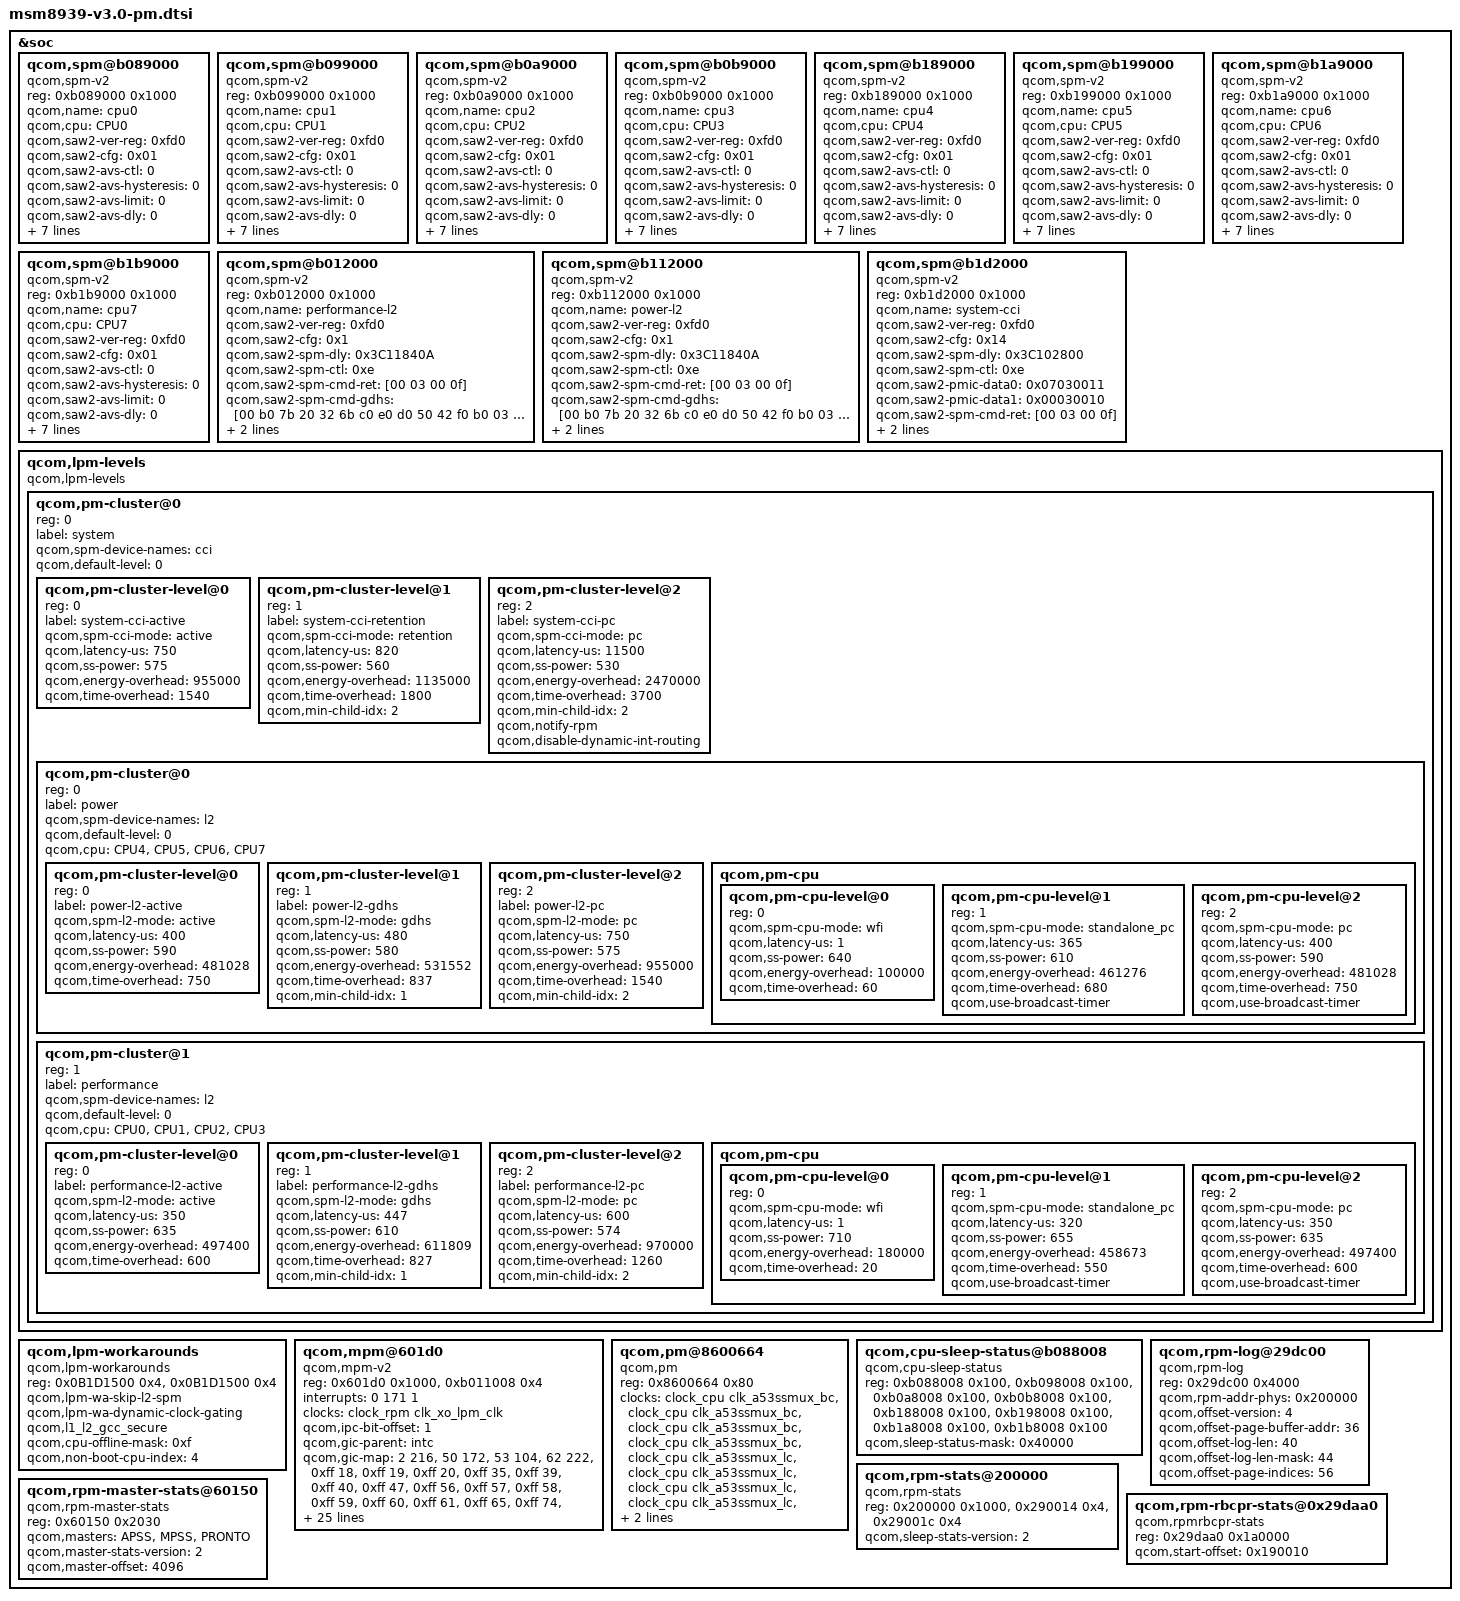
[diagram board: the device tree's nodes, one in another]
/* Copyright (c) 2014-2015, The Linux Foundation. All rights reserved.
 *
 * This program is free software; you can redistribute it and/or modify
 * it under the terms of the GNU General Public License version 2 and
 * only version 2 as published by the Free Software Foundation.
 *
 * This program is distributed in the hope that it will be useful,
 * but WITHOUT ANY WARRANTY; without even the implied warranty of
 * MERCHANTABILITY or FITNESS FOR A PARTICULAR PURPOSE.  See the
 * GNU General Public License for more details.
 */

&soc {
	qcom,spm@b089000 {
		compatible = "qcom,spm-v2";
		reg = <0xb089000 0x1000>;
		qcom,name = "cpu0";
		qcom,cpu = <&CPU0>;
		qcom,saw2-ver-reg = <0xfd0>;
		qcom,saw2-cfg = <0x01>;
		qcom,saw2-avs-ctl = <0>;
		qcom,saw2-avs-hysteresis = <0>;
		qcom,saw2-avs-limit = <0>;
		qcom,saw2-avs-dly= <0>;
		qcom,saw2-spm-dly= <0x3c102800>;
		qcom,saw2-spm-ctl = <0xe>;
		qcom,saw2-spm-cmd-wfi = [60 03 60 0b 0f];
		qcom,saw2-spm-cmd-spc = [20 50 1b 10 80 30 90 5b 60 50 03 60
				76 76 0b 50 1b 94 5B 80 10 26 30 50 0f];
		qcom,saw2-spm-cmd-pc = [20 50 1b 10 80 30 90 5b 60 50 03 60
				76 76 0b 50 1b 94 5B 80 10 26 30 50 0f];
	};

	qcom,spm@b099000 {
		compatible = "qcom,spm-v2";
		reg = <0xb099000 0x1000>;
		qcom,name = "cpu1";
		qcom,cpu = <&CPU1>;
		qcom,saw2-ver-reg = <0xfd0>;
		qcom,saw2-cfg = <0x01>;
		qcom,saw2-avs-ctl = <0>;
		qcom,saw2-avs-hysteresis = <0>;
		qcom,saw2-avs-limit = <0>;
		qcom,saw2-avs-dly= <0>;
		qcom,saw2-spm-dly= <0x3c102800>;
		qcom,saw2-spm-ctl = <0xe>;
		qcom,saw2-spm-cmd-wfi = [60 03 60 0b 0f];
		qcom,saw2-spm-cmd-spc = [20 50 1b 10 80 30 90 5b 60 50 03 60
				76 76 0b 50 1b 94 5B 80 10 26 30 50 0f];
		qcom,saw2-spm-cmd-pc = [20 50 1b 10 80 30 90 5b 60 50 03 60
				76 76 0b 50 1b 94 5B 80 10 26 30 50 0f];
	};

	qcom,spm@b0a9000 {
		compatible = "qcom,spm-v2";
		reg = <0xb0a9000 0x1000>;
		qcom,name = "cpu2";
		qcom,cpu = <&CPU2>;
		qcom,saw2-ver-reg = <0xfd0>;
		qcom,saw2-cfg = <0x01>;
		qcom,saw2-avs-ctl = <0>;
		qcom,saw2-avs-hysteresis = <0>;
		qcom,saw2-avs-limit = <0>;
		qcom,saw2-avs-dly= <0>;
		qcom,saw2-spm-dly= <0x3c102800>;
		qcom,saw2-spm-ctl = <0xe>;
		qcom,saw2-spm-cmd-wfi = [60 03 60 0b 0f];
		qcom,saw2-spm-cmd-spc = [20 50 1b 10 80 30 90 5b 60 50 03 60
				76 76 0b 50 1b 94 5B 80 10 26 30 50 0f];
		qcom,saw2-spm-cmd-pc = [20 50 1b 10 80 30 90 5b 60 50 03 60
				76 76 0b 50 1b 94 5B 80 10 26 30 50 0f];
	};

	qcom,spm@b0b9000 {
		compatible = "qcom,spm-v2";
		reg = <0xb0b9000 0x1000>;
		qcom,name = "cpu3";
		qcom,cpu = <&CPU3>;
		qcom,saw2-ver-reg = <0xfd0>;
		qcom,saw2-cfg = <0x01>;
		qcom,saw2-avs-ctl = <0>;
		qcom,saw2-avs-hysteresis = <0>;
		qcom,saw2-avs-limit = <0>;
		qcom,saw2-avs-dly= <0>;
		qcom,saw2-spm-dly= <0x3c102800>;
		qcom,saw2-spm-ctl = <0xe>;
		qcom,saw2-spm-cmd-wfi = [60 03 60 0b 0f];
		qcom,saw2-spm-cmd-spc = [20 50 1b 10 80 30 90 5b 60 50 03 60
				76 76 0b 50 1b 94 5B 80 10 26 30 50 0f];
		qcom,saw2-spm-cmd-pc = [20 50 1b 10 80 30 90 5b 60 50 03 60
				76 76 0b 50 1b 94 5B 80 10 26 30 50 0f];
	};

	qcom,spm@b189000 {
		compatible = "qcom,spm-v2";
		reg = <0xb189000 0x1000>;
		qcom,name = "cpu4";
		qcom,cpu = <&CPU4>;
		qcom,saw2-ver-reg = <0xfd0>;
		qcom,saw2-cfg = <0x01>;
		qcom,saw2-avs-ctl = <0>;
		qcom,saw2-avs-hysteresis = <0>;
		qcom,saw2-avs-limit = <0>;
		qcom,saw2-avs-dly= <0>;
		qcom,saw2-spm-dly= <0x3c102800>;
		qcom,saw2-spm-ctl = <0xe>;
		qcom,saw2-spm-cmd-wfi = [60 03 60 0b 0f];
		qcom,saw2-spm-cmd-spc = [20 50 1b 10 80 30 90 5b 60 50 03 60
				76 76 0b 50 1b 94 5B 80 10 26 30 50 0f];
		qcom,saw2-spm-cmd-pc = [20 50 1b 10 80 30 90 5b 60 50 03 60
				76 76 0b 50 1b 94 5B 80 10 26 30 50 0f];
	};

	qcom,spm@b199000 {
		compatible = "qcom,spm-v2";
		reg = <0xb199000 0x1000>;
		qcom,name = "cpu5";
		qcom,cpu = <&CPU5>;
		qcom,saw2-ver-reg = <0xfd0>;
		qcom,saw2-cfg = <0x01>;
		qcom,saw2-avs-ctl = <0>;
		qcom,saw2-avs-hysteresis = <0>;
		qcom,saw2-avs-limit = <0>;
		qcom,saw2-avs-dly= <0>;
		qcom,saw2-spm-dly= <0x3c102800>;
		qcom,saw2-spm-ctl = <0xe>;
		qcom,saw2-spm-cmd-wfi = [60 03 60 0b 0f];
		qcom,saw2-spm-cmd-spc = [20 50 1b 10 80 30 90 5b 60 50 03 60
				76 76 0b 50 1b 94 5B 80 10 26 30 50 0f];
		qcom,saw2-spm-cmd-pc = [20 50 1b 10 80 30 90 5b 60 50 03 60
				76 76 0b 50 1b 94 5B 80 10 26 30 50 0f];
	};

	qcom,spm@b1a9000 {
		compatible = "qcom,spm-v2";
		reg = <0xb1a9000 0x1000>;
		qcom,name = "cpu6";
		qcom,cpu = <&CPU6>;
		qcom,saw2-ver-reg = <0xfd0>;
		qcom,saw2-cfg = <0x01>;
		qcom,saw2-avs-ctl = <0>;
		qcom,saw2-avs-hysteresis = <0>;
		qcom,saw2-avs-limit = <0>;
		qcom,saw2-avs-dly= <0>;
		qcom,saw2-spm-dly= <0x3c102800>;
		qcom,saw2-spm-ctl = <0xe>;
		qcom,saw2-spm-cmd-wfi = [60 03 60 0b 0f];
		qcom,saw2-spm-cmd-spc = [20 50 1b 10 80 30 90 5b 60 50 03 60
				76 76 0b 50 1b 94 5B 80 10 26 30 50 0f];
		qcom,saw2-spm-cmd-pc = [20 50 1b 10 80 30 90 5b 60 50 03 60
				76 76 0b 50 1b 94 5B 80 10 26 30 50 0f];
	};

	qcom,spm@b1b9000 {
		compatible = "qcom,spm-v2";
		reg = <0xb1b9000 0x1000>;
		qcom,name = "cpu7";
		qcom,cpu = <&CPU7>;
		qcom,saw2-ver-reg = <0xfd0>;
		qcom,saw2-cfg = <0x01>;
		qcom,saw2-avs-ctl = <0>;
		qcom,saw2-avs-hysteresis = <0>;
		qcom,saw2-avs-limit = <0>;
		qcom,saw2-avs-dly= <0>;
		qcom,saw2-spm-dly= <0x3c102800>;
		qcom,saw2-spm-ctl = <0xe>;
		qcom,saw2-spm-cmd-wfi = [60 03 60 0b 0f];
		qcom,saw2-spm-cmd-spc = [20 50 1b 10 80 30 90 5b 60 50 03 60
				76 76 0b 50 1b 94 5B 80 10 26 30 50 0f];
		qcom,saw2-spm-cmd-pc = [20 50 1b 10 80 30 90 5b 60 50 03 60
				76 76 0b 50 1b 94 5B 80 10 26 30 50 0f];
	};

	qcom,spm@b012000 {
		compatible = "qcom,spm-v2";
		reg = <0xb012000 0x1000>;
		qcom,name = "performance-l2";
		qcom,saw2-ver-reg = <0xfd0>;
		qcom,saw2-cfg = <0x1>;
		qcom,saw2-spm-dly= <0x3C11840A>;
		qcom,saw2-spm-ctl = <0xe>;
		qcom,saw2-spm-cmd-ret = [00 03 00 0f];
		qcom,saw2-spm-cmd-gdhs = [00 b0 7b 20 32 6b c0 e0 d0 50 42 f0 b0
			03 1f 1b b0 7b 4e 02 02 d0 e0 c0 22 6b 02 32 52
			f0 b0 0f];
		qcom,saw2-spm-cmd-pc = [00 b0 7b 32 10 e0 d0 6b c0 50 42 b0 03
			1f 1b b0 7b 4e 02 02 c0 d0 12 e0 6b 02 32 50 b0 0f];
	};

	qcom,spm@b112000 {
		compatible = "qcom,spm-v2";
		reg = <0xb112000 0x1000>;
		qcom,name = "power-l2";
		qcom,saw2-ver-reg = <0xfd0>;
		qcom,saw2-cfg = <0x1>;
		qcom,saw2-spm-dly= <0x3C11840A>;
		qcom,saw2-spm-ctl = <0xe>;
		qcom,saw2-spm-cmd-ret = [00 03 00 0f];
		qcom,saw2-spm-cmd-gdhs = [00 b0 7b 20 32 6b c0 e0 d0 50 42 f0 b0
			03 1f 1b b0 7b 4e 02 02 d0 e0 c0 22 6b 02 32 52
			f0 b0 0f];
		qcom,saw2-spm-cmd-pc = [00 b0 7b 32 10 e0 d0 6b c0 50 42 b0 03
			1f 1b b0 7b 4e 02 02 c0 d0 12 e0 6b 02 32 50 b0 0f];
	};

	qcom,spm@b1d2000 {
		compatible = "qcom,spm-v2";
		reg = <0xb1d2000 0x1000>;
		qcom,name = "system-cci";
		qcom,saw2-ver-reg = <0xfd0>;
		qcom,saw2-cfg = <0x14>;
		qcom,saw2-spm-dly= <0x3C102800>;
		qcom,saw2-spm-ctl = <0xe>;
		qcom,saw2-pmic-data0 = <0x07030011>;
		qcom,saw2-pmic-data1 = <0x00030010>;
                qcom,saw2-spm-cmd-ret = [00 03 00 0f];
                qcom,saw2-spm-cmd-pc = [00 60 50 11 07 70 7B 01 50
                                02 62 72 0f];
	};

	qcom,lpm-levels {
		compatible = "qcom,lpm-levels";
		#address-cells = <1>;
		#size-cells = <0>;

		qcom,pm-cluster@0 {
			reg = <0>;
			#address-cells = <1>;
			#size-cells = <0>;
			label = "system";
			qcom,spm-device-names = "cci";
			qcom,default-level=<0>;

			qcom,pm-cluster-level@0{
				reg = <0>;
				label = "system-cci-active";
				qcom,spm-cci-mode = "active";
				qcom,latency-us = <750>;
				qcom,ss-power = <575>;
				qcom,energy-overhead = <955000>;
				qcom,time-overhead = <1540>;
			};

			qcom,pm-cluster-level@1{
				reg = <1>;
				label = "system-cci-retention";
				qcom,spm-cci-mode = "retention";
				qcom,latency-us = <820>;
				qcom,ss-power = <560>;
				qcom,energy-overhead = <1135000>;
				qcom,time-overhead = <1800>;
				qcom,min-child-idx = <2>;
			};

			qcom,pm-cluster-level@2{
				reg = <2>;
				label = "system-cci-pc";
				qcom,spm-cci-mode = "pc";
				qcom,latency-us = <11500>;
				qcom,ss-power = <530>;
				qcom,energy-overhead = <2470000>;
				qcom,time-overhead = <3700>;
				qcom,min-child-idx = <2>;
				qcom,notify-rpm;
				qcom,disable-dynamic-int-routing;
			};

			qcom,pm-cluster@0{
				reg = <0>;
				#address-cells = <1>;
				#size-cells = <0>;
				label = "power";
				qcom,spm-device-names = "l2";
				qcom,default-level=<0>;
				qcom,cpu = <&CPU4 &CPU5 &CPU6 &CPU7>;

				qcom,pm-cluster-level@0{
					reg = <0>;
					label = "power-l2-active";
					qcom,spm-l2-mode = "active";
					qcom,latency-us = <400>;
					qcom,ss-power = <590>;
					qcom,energy-overhead = <481028>;
					qcom,time-overhead = <750>;
				};

				qcom,pm-cluster-level@1{
					reg = <1>;
					label = "power-l2-gdhs";
					qcom,spm-l2-mode = "gdhs";
					qcom,latency-us = <480>;
					qcom,ss-power = <580>;
					qcom,energy-overhead = <531552>;
					qcom,time-overhead = <837>;
					qcom,min-child-idx = <1>;
				};

				qcom,pm-cluster-level@2{
					reg = <2>;
					label = "power-l2-pc";
					qcom,spm-l2-mode = "pc";
					qcom,latency-us = <750>;
					qcom,ss-power = <575>;
					qcom,energy-overhead = <955000>;
					qcom,time-overhead = <1540>;
					qcom,min-child-idx = <2>;
				};

				qcom,pm-cpu {
					#address-cells = <1>;
					#size-cells = <0>;

					qcom,pm-cpu-level@0 {
						reg = <0>;
						qcom,spm-cpu-mode = "wfi";
						qcom,latency-us = <1>;
						qcom,ss-power = <640>;
						qcom,energy-overhead = <100000>;
						qcom,time-overhead = <60>;
					};

					qcom,pm-cpu-level@1 {
						reg = <1>;
						qcom,spm-cpu-mode = "standalone_pc";
						qcom,latency-us = <365>;
						qcom,ss-power = <610>;
						qcom,energy-overhead = <461276>;
						qcom,time-overhead = <680>;
						qcom,use-broadcast-timer;
					};

					qcom,pm-cpu-level@2 {
						reg = <2>;
						qcom,spm-cpu-mode = "pc";
						qcom,latency-us = <400>;
						qcom,ss-power = <590>;
						qcom,energy-overhead = <481028>;
						qcom,time-overhead = <750>;
						qcom,use-broadcast-timer;
					};
				};
			};

			qcom,pm-cluster@1{
				reg = <1>;
				#address-cells = <1>;
				#size-cells = <0>;
				label = "performance";
				qcom,spm-device-names = "l2";
				qcom,default-level=<0>;
				qcom,cpu = <&CPU0 &CPU1 &CPU2 &CPU3>;

				qcom,pm-cluster-level@0{
					reg = <0>;
					label = "performance-l2-active";
					qcom,spm-l2-mode = "active";
					qcom,latency-us = <350>;
					qcom,ss-power = <635>;
					qcom,energy-overhead = <497400>;
					qcom,time-overhead = <600>;
				};

				qcom,pm-cluster-level@1{
					reg = <1>;
					label = "performance-l2-gdhs";
					qcom,spm-l2-mode = "gdhs";
					qcom,latency-us = <447>;
					qcom,ss-power = <610>;
					qcom,energy-overhead = <611809>;
					qcom,time-overhead = <827>;
					qcom,min-child-idx = <1>;
				};

				qcom,pm-cluster-level@2{
					reg = <2>;
					label = "performance-l2-pc";
					qcom,spm-l2-mode = "pc";
					qcom,latency-us = <600>;
					qcom,ss-power = <574>;
					qcom,energy-overhead = <970000>;
					qcom,time-overhead = <1260>;
					qcom,min-child-idx = <2>;
				};

				qcom,pm-cpu {
					#address-cells = <1>;
					#size-cells = <0>;

					qcom,pm-cpu-level@0 {
						reg = <0>;
						qcom,spm-cpu-mode = "wfi";
						qcom,latency-us = <1>;
						qcom,ss-power = <710>;
						qcom,energy-overhead = <180000>;
						qcom,time-overhead = <20>;
					};

					qcom,pm-cpu-level@1 {
						reg = <1>;
						qcom,spm-cpu-mode = "standalone_pc";
						qcom,latency-us = <320>;
						qcom,ss-power = <655>;
						qcom,energy-overhead = <458673>;
						qcom,time-overhead = <550>;
						qcom,use-broadcast-timer;
					};

					qcom,pm-cpu-level@2 {
						reg = <2>;
						qcom,spm-cpu-mode = "pc";
						qcom,latency-us = <350>;
						qcom,ss-power = <635>;
						qcom,energy-overhead = <497400>;
						qcom,time-overhead = <600>;
						qcom,use-broadcast-timer;
					};
				};
			};
		};
	};

	qcom,lpm-workarounds {
		compatible = "qcom,lpm-workarounds";
		reg = <0x0B1D1500 0x4>,
		      <0x0B1D1500 0x4>;
		reg-names = "l2-pwr-sts", "l1-l2-gcc";
		qcom,lpm-wa-skip-l2-spm;
		qcom,lpm-wa-dynamic-clock-gating;
		qcom,l1_l2_gcc_secure;
		qcom,cpu-offline-mask = <0xf>;
		qcom,non-boot-cpu-index = <4>;
	};

	qcom,mpm@601d0 {
		compatible = "qcom,mpm-v2";
		reg = <0x601d0 0x1000>, /* MSM_RPM_MPM_BASE 4K */
		    <0xb011008 0x4>;
		reg-names = "vmpm", "ipc";
		interrupts = <0 171 1>;
		clocks = <&clock_rpm clk_xo_lpm_clk>;
		clock-names = "xo";

		qcom,ipc-bit-offset = <1>;

		qcom,gic-parent = <&intc>;
		qcom,gic-map = <2 216>, /* tsens_upper_lower_int */
			<50 172>, /* usb1_hs_async_wakeup_irq */
			<53 104>, /* mdss_irq */
			<62 222>, /* ee0_krait_hlos_spmi_periph_irq */
			<0xff 18>,  /* APC_qgicQTmrSecPhysIrptReq */
			<0xff 19>,  /* APC_qgicQTmrNonSecPhysIrptReq */
			<0xff 20>,  /* qgicQTmrVirtIrptReq */
			<0xff 35>,  /* WDT_barkInt */
			<0xff 39>,  /* arch_mem_timer */
			<0xff 40>,  /* qtmr_phy_irq[0] */
			<0xff 47>,  /* rbif_irq[0] */
			<0xff 56>,  /* q6_wdog_expired_irq */
			<0xff 57>,  /* mss_to_apps_irq(0) */
			<0xff 58>,  /* mss_to_apps_irq(1) */
			<0xff 59>,  /* mss_to_apps_irq(2) */
			<0xff 60>,  /* mss_to_apps_irq(3) */
			<0xff 61>,  /* mss_a2_bam_irq */
			<0xff 65>,  /* o_gc_sys_irq[0] */
			<0xff 74>,  /* smmu_bus_intr[2] */
			<0xff 75>,  /* smmu_bus_intr[3] */
			<0xff 78>,  /* smmu_bus_intr[5] */
			<0xff 79>,  /* smmu_bus_intr[6] */
			<0xff 85>,  /* smmu_bus_intr[31] */
			<0xff 86>,  /* smmu_bus_intr[32] */
			<0xff 90>,  /* smmu_bus_intr[33] */
			<0xff 92>,  /* smmu_bus_intr[34] */
			<0xff 93>,  /* smmu_bus_intr[35] */
			<0xff 97>,  /* smmu_bus_intr[10] */
			<0xff 102>, /* smmu_bus_intr[14] */
			<0xff 108>, /* smmu_bus_intr[36] */
			<0xff 109>, /* smmu_bus_intr[37] */
			<0xff 112>, /* smmu_bus_intr[38] */
			<0xff 131>, /* qup_irq */
			<0xff 140>, /* uart_dm_intr */
			<0xff 142>, /* smmu_bus_intr[47] */
			<0xff 143>, /* smmu_bus_intr[48] */
			<0xff 144>, /* smmu_bus_intr[49] */
			<0xff 145>, /* smmu_bus_intr[50] */
			<0xff 146>, /* smmu_bus_intr[51] */
			<0xff 147>, /* smmu_bus_intr[52] */
			<0xff 148>, /* smmu_bus_intr[53] */
			<0xff 149>, /* smmu_bus_intr[54] */
			<0xff 150>, /* smmu_bus_intr[55] */
			<0xff 151>, /* smmu_bus_intr[56] */
			<0xff 152>, /* smmu_bus_intr[57] */
			<0xff 153>, /* smmu_bus_intr[58] */
			<0xff 155>, /* sdc1_irq(0) */
			<0xff 157>, /* sdc2_irq(0) */
			<0xff 166>, /* usb_hs_irq */
			<0xff 170>, /* sdc1_pwr_cmd_irq */
			<0xff 173>, /* o_wcss_apss_smd_hi */
			<0xff 174>, /* o_wcss_apss_smd_med */
			<0xff 175>, /* o_wcss_apss_smd_low */
			<0xff 176>, /* o_wcss_apss_smsm_irq */
			<0xff 177>, /* o_wcss_apss_wlan_data_xfer_done */
			<0xff 178>, /* o_wcss_apss_wlan_rx_data_avail */
			<0xff 179>, /* o_wcss_apss_asic_intr */
			<0xff 181>, /* o_wcss_apss_wdog_bite_and_reset_rdy */

			<0xff 188>, /* lpass_irq_out_apcs(0) */
			<0xff 189>, /* lpass_irq_out_apcs(1) */
			<0xff 190>, /* lpass_irq_out_apcs(2) */
			<0xff 191>, /* lpass_irq_out_apcs(3) */
			<0xff 192>, /* lpass_irq_out_apcs(4) */
			<0xff 193>, /* lpass_irq_out_apcs(5) */
			<0xff 194>, /* lpass_irq_out_apcs(6) */
			<0xff 195>, /* lpass_irq_out_apcs(7) */
			<0xff 196>, /* lpass_irq_out_apcs(8) */
			<0xff 197>, /* lpass_irq_out_apcs(9) */
			<0xff 198>, /* coresight-tmc-etr interrupt */
			<0xff 200>, /* rpm_ipc(4) */
			<0xff 201>, /* rpm_ipc(5) */
			<0xff 202>, /* rpm_ipc(6) */
			<0xff 203>, /* rpm_ipc(7) */
			<0xff 204>, /* rpm_ipc(24) */
			<0xff 205>, /* rpm_ipc(25) */
			<0xff 206>, /* rpm_ipc(26) */
			<0xff 207>, /* rpm_ipc(27) */
			<0xff 239>, /* crypto_bam_irq[1]*/
			<0xff 240>, /* summary_irq_kpss */
			<0xff 253>, /* sdc2_pwr_cmd_irq */
			<0xff 269>, /* rpm_wdog_expired_irq */
			<0xff 270>, /* blsp1_bam_irq[0] */
			<0xff 273>, /* smmu_bus_intr[18] */
			<0xff 274>, /* smmu_bus_intr[19] */
			<0xff 275>, /* rpm_ipc(30) */
			<0xff 276>; /* rpm_ipc(31) */

		qcom,gpio-parent = <&msm_gpio>;
		qcom,gpio-map = <3  108 >,
			<4  1 >,
			<5  5 >,
			<6  9 >,
			<7  107>,
			<8  98>,
			<9  97>,
			<10  11>,
			<11  69>,
			<12  12>,
			<13  13>,
			<14  20>,
			<15  62>,
			<16  54>,
			<17  21>,
			<18  52>,
			<19  25>,
			<20  51>,
			<21  50>,
			<22  28>,
			<23  31>,
			<24  34>,
			<25  35>,
			<26  36>,
			<27  37>,
			<28  38>,
			<29  49>,
			<30  109>,
			<31  110>,
			<32  111>,
			<33  112>,
			<34  113>,
			<35  114>,
			<36  115>,
			<37  117>,
			<38  118>,
			<39  120>,
			<40  121>,
			<50  66>,
			<51  68>;
	};

	qcom,pm@8600664 {
		compatible = "qcom,pm";
		ranges;
		reg = <0x8600664 0x80>;
		clock-names =
			"cpu0_clk", "cpu1_clk", "cpu2_clk",
			"cpu3_clk", "cpu4_clk", "cpu5_clk",
			"cpu6_clk", "cpu7_clk", "l2_clk";
		clocks = <&clock_cpu clk_a53ssmux_bc>,
			 <&clock_cpu clk_a53ssmux_bc>,
			 <&clock_cpu clk_a53ssmux_bc>,
			 <&clock_cpu clk_a53ssmux_bc>,
			 <&clock_cpu clk_a53ssmux_lc>,
			 <&clock_cpu clk_a53ssmux_lc>,
			 <&clock_cpu clk_a53ssmux_lc>,
			 <&clock_cpu clk_a53ssmux_lc>,
			 <&clock_cpu clk_a53ssmux_cci>;

		qcom,tz-flushes-cache;
	};

	qcom,cpu-sleep-status@b088008{
		compatible = "qcom,cpu-sleep-status";
		reg = <0xb088008 0x100>,
			<0xb098008 0x100>,
			<0xb0a8008 0x100>,
			<0xb0b8008 0x100>,
			<0xb188008 0x100>,
			<0xb198008 0x100>,
			<0xb1a8008 0x100>,
			<0xb1b8008 0x100>;
		qcom,sleep-status-mask= <0x40000>;
	};

	qcom,rpm-log@29dc00 {
		compatible = "qcom,rpm-log";
		reg = <0x29dc00 0x4000>;
		qcom,rpm-addr-phys = <0x200000>;
		qcom,offset-version = <4>;
		qcom,offset-page-buffer-addr = <36>;
		qcom,offset-log-len = <40>;
		qcom,offset-log-len-mask = <44>;
		qcom,offset-page-indices = <56>;
	};

	qcom,rpm-stats@200000 {
		compatible = "qcom,rpm-stats";
		reg = <0x200000 0x1000>,
		      <0x290014 0x4>,
		      <0x29001c 0x4>;
		reg-names = "phys_addr_base", "offset_addr", "heap_phys_addrbase";
		qcom,sleep-stats-version = <2>;
	};

	qcom,rpm-master-stats@60150 {
		compatible = "qcom,rpm-master-stats";
		reg = <0x60150 0x2030>;
		qcom,masters = "APSS", "MPSS", "PRONTO";
		qcom,master-stats-version = <2>;
		qcom,master-offset = <4096>;
	};

	qcom,rpm-rbcpr-stats@0x29daa0  {
		compatible = "qcom,rpmrbcpr-stats";
		reg = <0x29daa0 0x1a0000>;
		qcom,start-offset = <0x190010>;
	};
};
